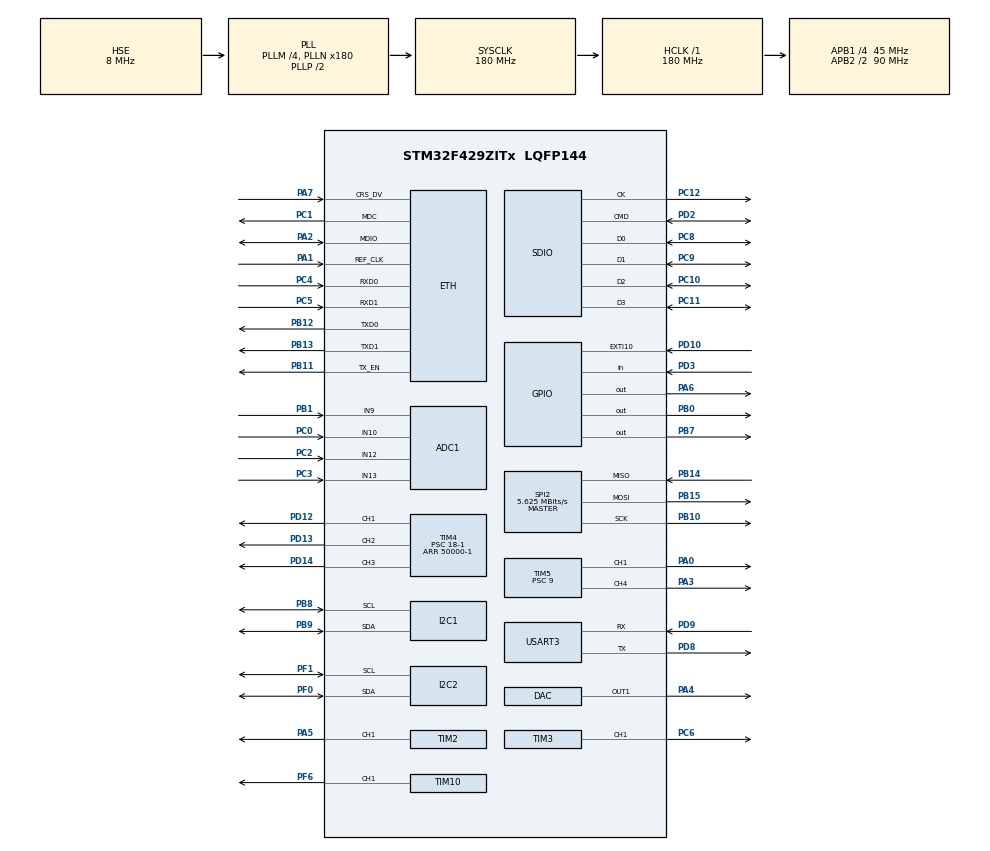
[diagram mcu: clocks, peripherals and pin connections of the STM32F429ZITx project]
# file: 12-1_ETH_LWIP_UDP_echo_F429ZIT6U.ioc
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ADC1.Channel-0\#ChannelRegularConversion=ADC_CHANNEL_10
ADC1.Channel-1\#ChannelRegularConversion=ADC_CHANNEL_12
ADC1.Channel-2\#ChannelRegularConversion=ADC_CHANNEL_13
ADC1.Channel-3\#ChannelRegularConversion=ADC_CHANNEL_9
ADC1.ContinuousConvMode=ENABLE
ADC1.DMAContinuousRequests=ENABLE
ADC1.DataAlign=ADC_DATAALIGN_RIGHT
ADC1.EOCSelection=ADC_EOC_SINGLE_CONV
ADC1.EnableAnalogWatchDog=false
ADC1.InjNumberOfConversion=0
ADC1.NbrOfConversion=4
ADC1.NbrOfConversionFlag=1
ADC1.Rank-0\#ChannelRegularConversion=1
ADC1.Rank-1\#ChannelRegularConversion=2
ADC1.Rank-2\#ChannelRegularConversion=3
ADC1.Rank-3\#ChannelRegularConversion=4
ADC1.SamplingTime-0\#ChannelRegularConversion=ADC_SAMPLETIME_84CYCLES
ADC1.SamplingTime-1\#ChannelRegularConversion=ADC_SAMPLETIME_84CYCLES
ADC1.SamplingTime-2\#ChannelRegularConversion=ADC_SAMPLETIME_84CYCLES
ADC1.SamplingTime-3\#ChannelRegularConversion=ADC_SAMPLETIME_84CYCLES
ADC1.ScanConvMode=ENABLE
ADC1.master=1
Dma.ADC1.0.Direction=DMA_PERIPH_TO_MEMORY
Dma.ADC1.0.FIFOMode=DMA_FIFOMODE_DISABLE
Dma.ADC1.0.Instance=DMA2_Stream0
Dma.ADC1.0.MemDataAlignment=DMA_MDATAALIGN_HALFWORD
Dma.ADC1.0.MemInc=DMA_MINC_ENABLE
Dma.ADC1.0.Mode=DMA_CIRCULAR
Dma.ADC1.0.PeriphDataAlignment=DMA_PDATAALIGN_HALFWORD
Dma.ADC1.0.PeriphInc=DMA_PINC_DISABLE
Dma.ADC1.0.Priority=DMA_PRIORITY_LOW
Dma.Request0=ADC1
Dma.Request1=SDIO_TX
Dma.Request2=SDIO_RX
Dma.SDIO_RX.2.Direction=DMA_PERIPH_TO_MEMORY
Dma.SDIO_RX.2.FIFOMode=DMA_FIFOMODE_ENABLE
Dma.SDIO_RX.2.FIFOThreshold=DMA_FIFO_THRESHOLD_FULL
Dma.SDIO_RX.2.Instance=DMA2_Stream6
Dma.SDIO_RX.2.MemBurst=DMA_MBURST_INC4
Dma.SDIO_RX.2.MemDataAlignment=DMA_MDATAALIGN_WORD
Dma.SDIO_RX.2.MemInc=DMA_MINC_ENABLE
Dma.SDIO_RX.2.Mode=DMA_PFCTRL
Dma.SDIO_RX.2.PeriphBurst=DMA_PBURST_INC4
Dma.SDIO_RX.2.PeriphDataAlignment=DMA_PDATAALIGN_WORD
Dma.SDIO_RX.2.PeriphInc=DMA_PINC_DISABLE
Dma.SDIO_RX.2.Priority=DMA_PRIORITY_LOW
Dma.SDIO_TX.1.Direction=DMA_MEMORY_TO_PERIPH
Dma.SDIO_TX.1.FIFOMode=DMA_FIFOMODE_ENABLE
Dma.SDIO_TX.1.FIFOThreshold=DMA_FIFO_THRESHOLD_FULL
Dma.SDIO_TX.1.Instance=DMA2_Stream3
Dma.SDIO_TX.1.MemBurst=DMA_MBURST_INC4
Dma.SDIO_TX.1.MemDataAlignment=DMA_MDATAALIGN_WORD
Dma.SDIO_TX.1.MemInc=DMA_MINC_ENABLE
Dma.SDIO_TX.1.Mode=DMA_PFCTRL
Dma.SDIO_TX.1.PeriphBurst=DMA_PBURST_INC4
Dma.SDIO_TX.1.PeriphDataAlignment=DMA_PDATAALIGN_WORD
Dma.SDIO_TX.1.PeriphInc=DMA_PINC_DISABLE
Dma.SDIO_TX.1.Priority=DMA_PRIORITY_LOW
ETH.MediaInterface=ETH_MEDIA_INTERFACE_RMII
FATFS.BSP.number=1
FATFS.USE_DMA_CODE_SD=1
FATFS._USE_LFN=1
FATFS0.BSP.STBoard=false
FATFS0.BSP.api=Unknown
FATFS0.BSP.i2caddr=0
FATFS0.BSP.instance=PD3
FATFS0.BSP.ip=GPIO
FATFS0.BSP.mode=Input
FATFS0.BSP.name=Detect_SDIO
FATFS0.BSP.solution=PD3
I2C1.I2C_Mode=I2C_Fast
LWIP.CHECKSUM_BY_HARDWARE=0
LWIP.GATEWAY_ADDRESS=192.168.000.001
LWIP.IP_ADDRESS=192.168.000.235
LWIP.LWIP_DHCP=0
LWIP.NETMASK_ADDRESS=255.255.255.000
LWIP.Version=v2.1.2_Cube
Mcu.Family=STM32F4
Mcu.Name=STM32F429ZITx
Mcu.Package=LQFP144
NVIC.DMA2_Stream0_IRQn=true\:0\:0\:false\:false\:true\:false\:true\:true
NVIC.DMA2_Stream3_IRQn=true\:0\:0\:false\:false\:true\:false\:true\:true
NVIC.DMA2_Stream6_IRQn=true\:0\:0\:false\:false\:true\:false\:true\:true
NVIC.EXTI15_10_IRQn=true\:0\:0\:false\:false\:true\:true\:true\:true
NVIC.PriorityGroup=NVIC_PRIORITYGROUP_4
NVIC.SDIO_IRQn=true\:0\:0\:false\:false\:true\:true\:true\:true
NVIC.TIM4_IRQn=true\:0\:0\:false\:false\:true\:true\:true\:true
NVIC.TIM7_IRQn=true\:0\:0\:false\:false\:true\:true\:true\:true
NVIC.USART3_IRQn=true\:0\:0\:false\:false\:true\:true\:true\:true
PA0/WKUP.Signal=S_TIM5_CH1
PA1.Mode=RMII
PA1.Signal=ETH_REF_CLK
PA2.Mode=RMII
PA2.Signal=ETH_MDIO
PA3.Signal=S_TIM5_CH4
PA4.Signal=COMP_DAC1_group
PA5.Signal=S_TIM2_CH1_ETR
PA6.Signal=GPIO_Output
PA7.Mode=RMII
PA7.Signal=ETH_CRS_DV
PB0.Signal=GPIO_Output
PB1.Signal=ADCx_IN9
PB10.Mode=Full_Duplex_Master
PB10.Signal=SPI2_SCK
PB11.Mode=RMII
PB11.Signal=ETH_TX_EN
PB12.Mode=RMII
PB12.Signal=ETH_TXD0
PB13.Mode=RMII
PB13.Signal=ETH_TXD1
PB14.Mode=Full_Duplex_Master
PB14.Signal=SPI2_MISO
PB15.Mode=Full_Duplex_Master
PB15.Signal=SPI2_MOSI
PB7.Signal=GPIO_Output
PB8.Mode=I2C
PB8.Signal=I2C1_SCL
PB9.Mode=I2C
PB9.Signal=I2C1_SDA
PC0.Signal=ADCx_IN10
PC1.Mode=RMII
PC1.Signal=ETH_MDC
PC10.Mode=SD_4_bits_Wide_bus
PC10.Signal=SDIO_D2
PC11.Mode=SD_4_bits_Wide_bus
PC11.Signal=SDIO_D3
PC12.Mode=SD_4_bits_Wide_bus
PC12.Signal=SDIO_CK
PC2.Signal=ADCx_IN12
PC3.Signal=ADCx_IN13
PC4.Mode=RMII
PC4.Signal=ETH_RXD0
PC5.Mode=RMII
PC5.Signal=ETH_RXD1
PC6.Signal=S_TIM3_CH1
PC8.Mode=SD_4_bits_Wide_bus
PC8.Signal=SDIO_D0
PC9.Mode=SD_4_bits_Wide_bus
PC9.Signal=SDIO_D1
PD10.GPIO_PuPd=GPIO_PULLDOWN
PD10.Signal=GPXTI10
PD12.Signal=S_TIM4_CH1
PD13.Signal=S_TIM4_CH2
PD14.Signal=S_TIM4_CH3
PD2.Mode=SD_4_bits_Wide_bus
PD2.Signal=SDIO_CMD
PD3.Signal=GPIO_Input
PD8.Mode=Asynchronous
PD8.Signal=USART3_TX
PD9.Mode=Asynchronous
PD9.Signal=USART3_RX
PF0.Mode=I2C
PF0.Signal=I2C2_SDA
PF1.Mode=I2C
PF1.Signal=I2C2_SCL
PF6.Signal=S_TIM10_CH1
PH0/OSC_IN.Mode=HSE-External-Oscillator
PH0/OSC_IN.Signal=RCC_OSC_IN
PH1/OSC_OUT.Mode=HSE-External-Oscillator
PH1/OSC_OUT.Signal=RCC_OSC_OUT
ProjectManager.HeapSize=0x200
ProjectManager.StackSize=0x400
ProjectManager.TargetToolchain=STM32CubeIDE
RCC.48MHZClocksFreq_Value=45000000
RCC.AHBFreq_Value=180000000
RCC.APB1CLKDivider=RCC_HCLK_DIV4
RCC.APB1Freq_Value=45000000
RCC.APB1TimFreq_Value=90000000
RCC.APB2CLKDivider=RCC_HCLK_DIV2
RCC.APB2Freq_Value=90000000
RCC.APB2TimFreq_Value=180000000
RCC.CortexFreq_Value=180000000
RCC.HCLKFreq_Value=180000000
RCC.HSE_VALUE=8000000
RCC.HSI_VALUE=16000000
RCC.LSE_VALUE=32768
RCC.PLLM=4
RCC.PLLN=180
RCC.PLLQ=8
RCC.PLLSourceVirtual=RCC_PLLSOURCE_HSE
RCC.SYSCLKFreq_VALUE=180000000
RCC.SYSCLKSource=RCC_SYSCLKSOURCE_PLLCLK
RCC.VCOOutputFreq_Value=360000000
SH.ADCx_IN10.0=ADC1_IN10,IN10
SH.ADCx_IN12.0=ADC1_IN12,IN12
SH.ADCx_IN13.0=ADC1_IN13,IN13
SH.ADCx_IN9.0=ADC1_IN9,IN9
SH.COMP_DAC1_group.0=DAC_OUT1,DAC_OUT1
SH.S_TIM10_CH1.0=TIM10_CH1,PWM Generation1 CH1
SH.S_TIM2_CH1_ETR.0=TIM2_CH1,PWM Generation1 CH1
SH.S_TIM3_CH1.0=TIM3_CH1,PWM Generation1 CH1
SH.S_TIM4_CH1.0=TIM4_CH1,PWM Generation1 CH1
SH.S_TIM4_CH2.0=TIM4_CH2,PWM Generation2 CH2
SH.S_TIM4_CH3.0=TIM4_CH3,PWM Generation3 CH3
SH.S_TIM5_CH1.0=TIM5_CH1,PWM Generation1 CH1
SH.S_TIM5_CH4.0=TIM5_CH4,PWM Generation4 CH4
SPI2.BaudRatePrescaler=SPI_BAUDRATEPRESCALER_8
SPI2.CLKPhase=SPI_PHASE_2EDGE
SPI2.CLKPolarity=SPI_POLARITY_HIGH
SPI2.CalculateBaudRate=5.625 MBits/s
SPI2.Direction=SPI_DIRECTION_2LINES
SPI2.Mode=SPI_MODE_MASTER
SPI2.VirtualType=VM_MASTER
TIM10.Channel=TIM_CHANNEL_1
TIM10.Period=50000-1
TIM10.Prescaler=72-1
TIM10.Pulse=500
TIM2.Channel-PWM\ Generation1\ CH1=TIM_CHANNEL_1
TIM2.Period=1000-1
TIM2.Prescaler=180-1
TIM2.Pulse-PWM\ Generation1\ CH1=500
TIM3.Channel-PWM\ Generation1\ CH1=TIM_CHANNEL_1
TIM3.Period=50000-1
TIM3.Prescaler=9-1
TIM4.Channel-PWM\ Generation1\ CH1=TIM_CHANNEL_1
TIM4.Channel-PWM\ Generation2\ CH2=TIM_CHANNEL_2
TIM4.Channel-PWM\ Generation3\ CH3=TIM_CHANNEL_3
TIM4.Period=50000-1
TIM4.Prescaler=18-1
TIM4.Pulse-PWM\ Generation1\ CH1=25000-1
TIM4.Pulse-PWM\ Generation2\ CH2=12500-1
TIM4.Pulse-PWM\ Generation3\ CH3=7250-1
TIM5.Channel-PWM\ Generation1\ CH1=TIM_CHANNEL_1
TIM5.Channel-PWM\ Generation4\ CH4=TIM_CHANNEL_4
TIM5.Period=100000-1
TIM5.Prescaler=9
TIM7.AutoReloadPreload=TIM_AUTORELOAD_PRELOAD_ENABLE
TIM7.Period=9999
TIM7.Prescaler=8
USART3.VirtualMode=VM_ASYNC
VP_FATFS_VS_SDIO.Mode=SDIO
VP_LWIP_VS_Enabled.Mode=Enabled
VP_TIM10_VS_ClockSourceINT.Mode=Enable_Timer
VP_TIM2_VS_ClockSourceINT.Mode=Internal
VP_TIM3_VS_ClockSourceINT.Mode=Internal
VP_TIM4_VS_ClockSourceINT.Mode=Internal
VP_TIM5_VS_ClockSourceINT.Mode=Internal
VP_TIM7_VS_ClockSourceINT.Mode=Enable_Timer
board=custom

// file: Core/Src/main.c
/* USER CODE BEGIN Header */
/**
  ******************************************************************************
  * @file           : main.c
  * @brief          : Main program body
  ******************************************************************************
  * @attention
  *
  * Copyright (c) 2022 STMicroelectronics.
  * All rights reserved.
  *
  * This software is licensed under terms that can be found in the LICENSE file
  * in the root directory of this software component.
  * If no LICENSE file comes with this software, it is provided AS-IS.
  *
  ******************************************************************************
  */
/* USER CODE END Header */
#include "main.h"
#include "adc.h"
#include "dac.h"
#include "dma.h"
#include "fatfs.h"
#include "i2c.h"
#include "lwip.h"
#include "sdio.h"
#include "spi.h"
#include "tim.h"
#include "usart.h"
#include "gpio.h"

/* USER CODE BEGIN Includes */
#include <stdio.h>
#include "udp_echoserver.h"
/* USER CODE END Includes */

void SystemClock_Config(void);
/* USER CODE BEGIN PFP */
int _write(int file, char* p, int len)
{
	if(HAL_UART_Transmit(&huart3, (uint8_t*)p, len, 10) == HAL_OK) return len;
	else return 0;
}
/* USER CODE END PFP */

int main(void)
{

  /* MCU Configuration--------------------------------------------------------*/

  /* Reset of all peripherals, Initializes the Flash interface and the Systick. */
  HAL_Init();

  /* Configure the system clock */
  SystemClock_Config();

  /* Initialize all configured peripherals */
  MX_GPIO_Init();
  MX_USART3_UART_Init();
  MX_I2C1_Init();
  MX_TIM7_Init();
  MX_TIM3_Init();
  MX_TIM4_Init();
  MX_TIM10_Init();
  MX_TIM2_Init();
  MX_DMA_Init();
  MX_ADC1_Init();
  MX_TIM5_Init();
  MX_DAC_Init();
  MX_I2C2_Init();
  MX_SPI2_Init();
  MX_SDIO_SD_Init();
  MX_FATFS_Init();
  MX_LWIP_Init();
  /* USER CODE BEGIN 2 */

  /* tcp echo server Init */
  udp_echoserver_init();

  /* USER CODE END 2 */

  /* Infinite loop */
  /* USER CODE BEGIN WHILE */
  while (1)
  {
   /* Read a received packet from the Ethernet buffers and send it
	   to the lwIP for handling */
	ethernetif_input(&gnetif);

	/* Handle timeouts */
	sys_check_timeouts();

//	#if LWIP_NETIF_LINK_CALLBACK
//	    Ethernet_Link_Periodic_Handle(&gnetif);
//	#endif

//	#if LWIP_DHCP
//	    DHCP_Periodic_Handle(&gnetif);
//	#endif
    /* USER CODE END WHILE */

  }
}

void SystemClock_Config(void)
{
  RCC_OscInitTypeDef RCC_OscInitStruct = {0};
  RCC_ClkInitTypeDef RCC_ClkInitStruct = {0};

  /** Configure the main internal regulator output voltage
  */
  __HAL_RCC_PWR_CLK_ENABLE();
  __HAL_PWR_VOLTAGESCALING_CONFIG(PWR_REGULATOR_VOLTAGE_SCALE1);
  /** Initializes the RCC Oscillators according to the specified parameters
  * in the RCC_OscInitTypeDef structure.
  */
  RCC_OscInitStruct.OscillatorType = RCC_OSCILLATORTYPE_HSE;
  RCC_OscInitStruct.HSEState = RCC_HSE_ON;
  RCC_OscInitStruct.PLL.PLLState = RCC_PLL_ON;
  RCC_OscInitStruct.PLL.PLLSource = RCC_PLLSOURCE_HSE;
  RCC_OscInitStruct.PLL.PLLM = 4;
  RCC_OscInitStruct.PLL.PLLN = 180;
  RCC_OscInitStruct.PLL.PLLP = RCC_PLLP_DIV2;
  RCC_OscInitStruct.PLL.PLLQ = 8;
  if (HAL_RCC_OscConfig(&RCC_OscInitStruct) != HAL_OK)
  {
    Error_Handler();
  }
  /** Activate the Over-Drive mode
  */
  if (HAL_PWREx_EnableOverDrive() != HAL_OK)
  {
    Error_Handler();
  }
  /** Initializes the CPU, AHB and APB buses clocks
  */
  RCC_ClkInitStruct.ClockType = RCC_CLOCKTYPE_HCLK|RCC_CLOCKTYPE_SYSCLK
                              |RCC_CLOCKTYPE_PCLK1|RCC_CLOCKTYPE_PCLK2;
  RCC_ClkInitStruct.SYSCLKSource = RCC_SYSCLKSOURCE_PLLCLK;
  RCC_ClkInitStruct.AHBCLKDivider = RCC_SYSCLK_DIV1;
  RCC_ClkInitStruct.APB1CLKDivider = RCC_HCLK_DIV4;
  RCC_ClkInitStruct.APB2CLKDivider = RCC_HCLK_DIV2;

  if (HAL_RCC_ClockConfig(&RCC_ClkInitStruct, FLASH_LATENCY_5) != HAL_OK)
  {
    Error_Handler();
  }
}

void Error_Handler(void)
{
  __disable_irq();
  while (1)
  {
  }
}
